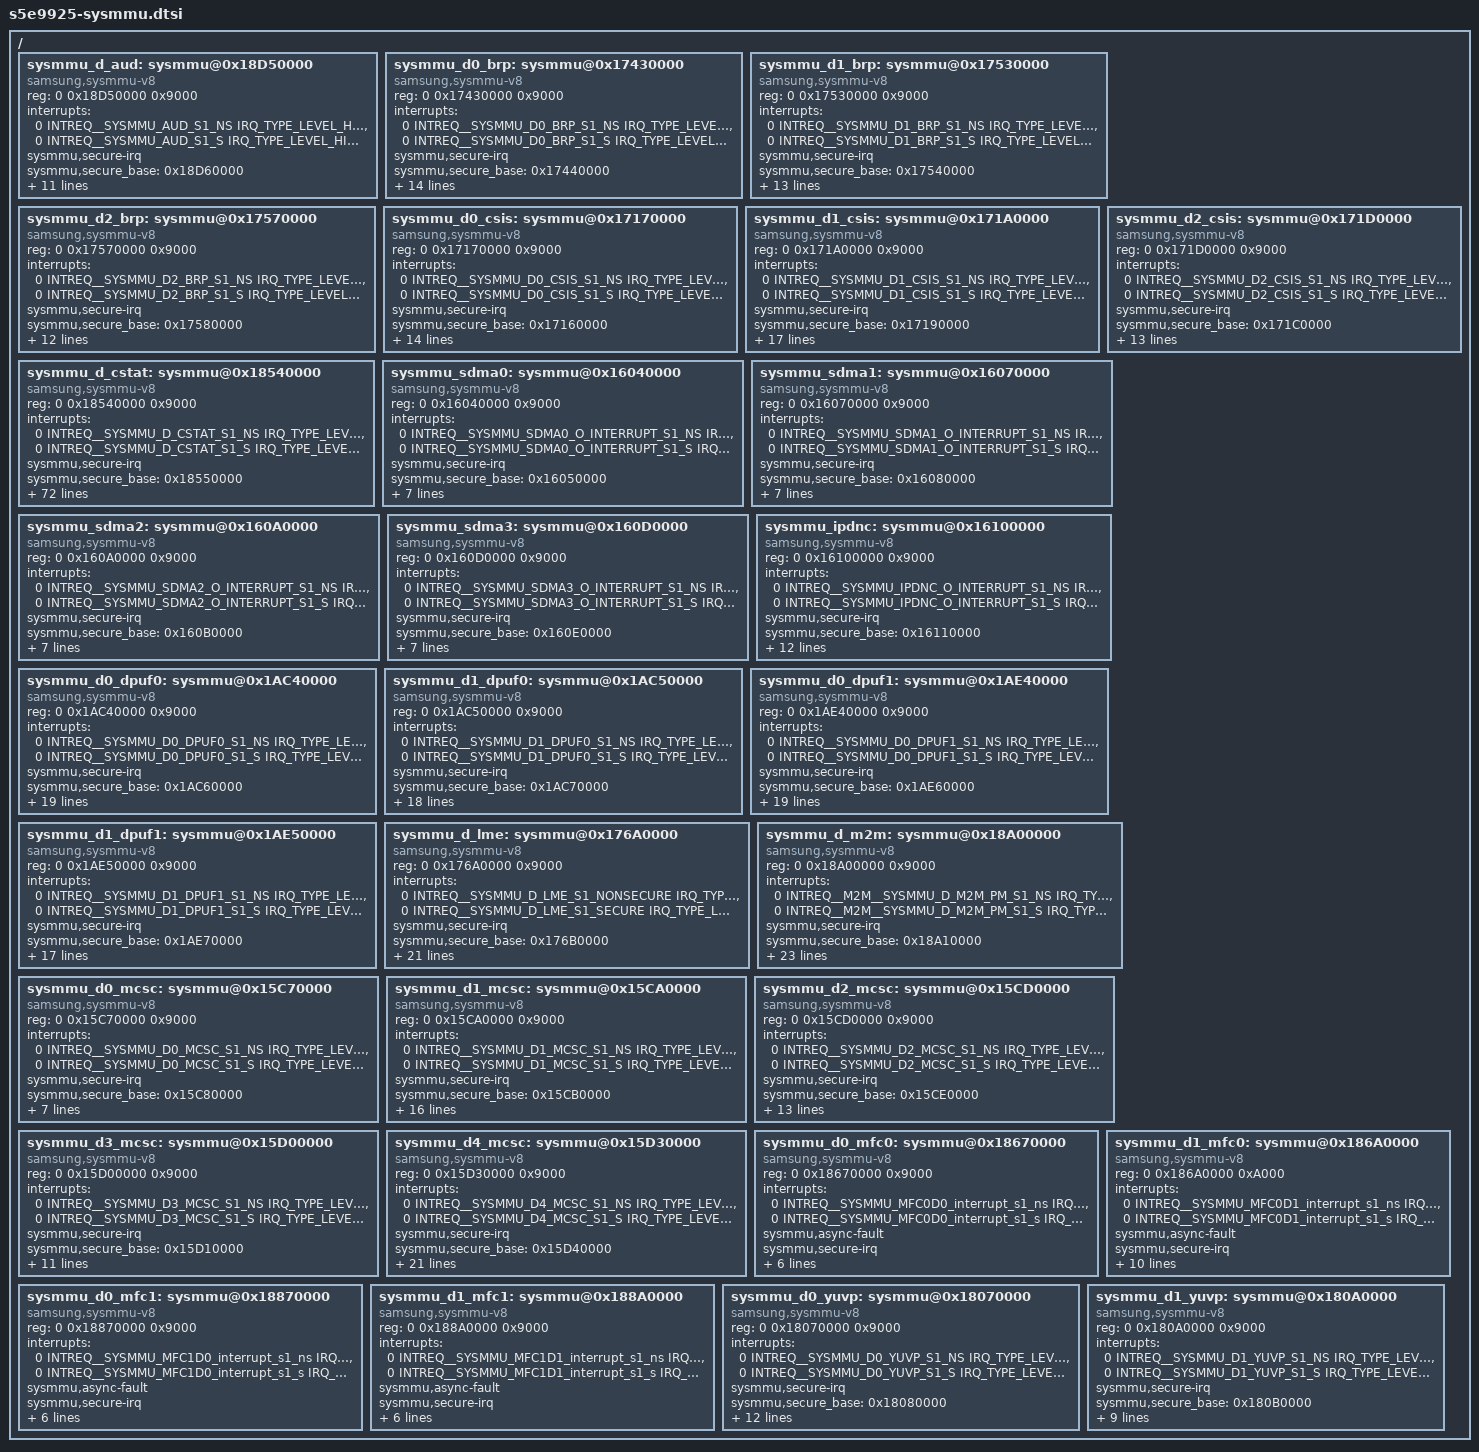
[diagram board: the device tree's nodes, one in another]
/*
 * SAMSUNG S5E9925 SoC device tree source
 *
 * Copyright (c) 2021 Samsung Electronics Co., Ltd.
 *		http://www.samsung.com
 *
 * SAMSUNG S5E9925 SoC device nodes are listed in this file.
 * S5E9925 based board files can include this file and provide
 * values for board specfic bindings.
 *
 * This program is free software; you can redistribute it and/or modify
 * it under the terms of the GNU General Public License version 2 as
 * published by the Free Software Foundation.
 */

#include <dt-bindings/interrupt-controller/arm-gic.h>
#include <dt-bindings/soc/samsung,sysmmu-v8.h>

/ {
	sysmmu_d_aud: sysmmu@0x18D50000 {
		compatible = "samsung,sysmmu-v8";
		reg = <0 0x18D50000 0x9000>;
		interrupts = <0 INTREQ__SYSMMU_AUD_S1_NS IRQ_TYPE_LEVEL_HIGH>,
				<0 INTREQ__SYSMMU_AUD_S1_S IRQ_TYPE_LEVEL_HIGH>;
		sysmmu,secure-irq;
		sysmmu,secure_base = <0x18D60000>;
		qos = <15>;
		#iommu-cells = <0>;
		sysmmu,default_tlb = <TLB_CFG(BL1, PREFETCH_NONE)>;
		sysmmu,tlb_property =
			<1 TLB_CFG(BL1, PREFETCH_NONE) DIR_RW SYSMMU_ID_MASK(0x3, 0xF)>,
			<2 TLB_CFG(BL1, PREFETCH_NONE) DIR_RW SYSMMU_ID_MASK(0x4, 0xF)>,
			<3 TLB_CFG(BL1, PREFETCH_NONE) DIR_RW SYSMMU_ID_MASK(0x5, 0xF)>,
			<4 TLB_CFG(BL1, PREFETCH_NONE) DIR_WRITE SYSMMU_ID_MASK(0x7, 0xF)>,
			<5 TLB_CFG(BL1, PREFETCH_NONE) DIR_WRITE SYSMMU_ID_MASK(0x8, 0xF)>;
		port-name = "ABOX (CA32_0), ABOX (UDMA), ...";
		power-domains = <&pd_aud>;
	};

	sysmmu_d0_brp: sysmmu@0x17430000 {
		compatible = "samsung,sysmmu-v8";
		reg = <0 0x17430000 0x9000>;
		interrupts = <0 INTREQ__SYSMMU_D0_BRP_S1_NS IRQ_TYPE_LEVEL_HIGH>,
				<0 INTREQ__SYSMMU_D0_BRP_S1_S IRQ_TYPE_LEVEL_HIGH>;
		sysmmu,secure-irq;
		sysmmu,secure_base = <0x17440000>;
		qos = <15>;
		#iommu-cells = <0>;
		sysmmu,default_tlb = <TLB_CFG(BL1, PREFETCH_PREDICTION)>;
		sysmmu,tlb_property =
			<1 TLB_CFG(BL1, PREFETCH_PREDICTION) DIR_READ SYSMMU_ID_MASK(0x0, 0xF)>,
			<2 TLB_CFG(BL1, PREFETCH_PREDICTION) DIR_READ SYSMMU_ID_MASK(0x8, 0xF)>,
			<8 TLB_CFG(BL1, PREFETCH_NONE) DIR_READ SYSMMU_ID_MASK(0x1, 0xF)>,
			<3 TLB_CFG(BL1, PREFETCH_PREDICTION) DIR_READ SYSMMU_ID_MASK(0x2, 0xF)>,
			<4 TLB_CFG(BL1, PREFETCH_PREDICTION) DIR_READ SYSMMU_ID_MASK(0xA, 0xF)>,
			<5 TLB_CFG(BL1, PREFETCH_NONE) DIR_WRITE SYSMMU_ID_MASK(0x3, 0xF)>,
			<6 TLB_CFG(BL1, PREFETCH_NONE) DIR_WRITE SYSMMU_ID_MASK(0x4, 0xF)>,
			<7 TLB_CFG(BL1, PREFETCH_NONE) DIR_WRITE SYSMMU_ID_MASK(0x5, 0xF)>;
		port-name = "BYRP(M0), BYRP(M1), BYRP(M2)...";
		power-domains = <&pd_brp>;
	};

	sysmmu_d1_brp: sysmmu@0x17530000 {
		compatible = "samsung,sysmmu-v8";
		reg = <0 0x17530000 0x9000>;
		interrupts = <0 INTREQ__SYSMMU_D1_BRP_S1_NS IRQ_TYPE_LEVEL_HIGH>,
				<0 INTREQ__SYSMMU_D1_BRP_S1_S IRQ_TYPE_LEVEL_HIGH>;
		sysmmu,secure-irq;
		sysmmu,secure_base = <0x17540000>;
		qos = <15>;
		#iommu-cells = <0>;
		sysmmu,default_tlb = <TLB_CFG(BL1, PREFETCH_PREDICTION)>;
		sysmmu,tlb_property =
			<7 TLB_CFG(BL1, PREFETCH_NONE) DIR_READ SYSMMU_ID_MASK(0x0, 0x7)>,
			<1 TLB_CFG(BL1, PREFETCH_PREDICTION) DIR_WRITE SYSMMU_ID_MASK(0x4, 0x7)>,
			<2 TLB_CFG(BL1, PREFETCH_PREDICTION) DIR_READ SYSMMU_ID_MASK(0x1, 0x7)>,
			<3 TLB_CFG(BL1, PREFETCH_PREDICTION) DIR_WRITE SYSMMU_ID_MASK(0x5, 0x7)>,
			<4 TLB_CFG(BL1, PREFETCH_PREDICTION) DIR_WRITE SYSMMU_ID_MASK(0x1, 0x7)>,
			<5 TLB_CFG(BL1, PREFETCH_PREDICTION) DIR_WRITE SYSMMU_ID_MASK(0x2, 0x7)>,
			<6 TLB_CFG(BL1, PREFETCH_NONE) DIR_WRITE SYSMMU_ID_MASK(0x3, 0x7)>;
		port-name = "RGBP (M0), RGBP (M0), RGBP (...";
		power-domains = <&pd_brp>;
	};

	sysmmu_d2_brp: sysmmu@0x17570000 {
		compatible = "samsung,sysmmu-v8";
		reg = <0 0x17570000 0x9000>;
		interrupts = <0 INTREQ__SYSMMU_D2_BRP_S1_NS IRQ_TYPE_LEVEL_HIGH>,
				<0 INTREQ__SYSMMU_D2_BRP_S1_S IRQ_TYPE_LEVEL_HIGH>;
		sysmmu,secure-irq;
		sysmmu,secure_base = <0x17580000>;
		qos = <15>;
		#iommu-cells = <0>;
		sysmmu,default_tlb = <TLB_CFG(BL1, PREFETCH_PREDICTION)>;
		sysmmu,tlb_property =
			<1 TLB_CFG(BL1, PREFETCH_PREDICTION) DIR_WRITE SYSMMU_ID_MASK(0x0, 0x7)>,
			<2 TLB_CFG(BL1, PREFETCH_PREDICTION) DIR_READ SYSMMU_ID_MASK(0x1, 0x7)>,
			<3 TLB_CFG(BL1, PREFETCH_PREDICTION) DIR_WRITE SYSMMU_ID_MASK(0x1, 0x7)>,
			<4 TLB_CFG(BL1, PREFETCH_PREDICTION) DIR_WRITE SYSMMU_ID_MASK(0x5, 0x7)>,
			<5 TLB_CFG(BL1, PREFETCH_PREDICTION) DIR_WRITE SYSMMU_ID_MASK(0x2, 0x7)>,
			<6 TLB_CFG(BL1, PREFETCH_NONE) DIR_WRITE SYSMMU_ID_MASK(0x3, 0x7)>;
		port-name = "RGBP (M1), RGBP (M1), RGBP (...";
		power-domains = <&pd_brp>;
	};

	sysmmu_d0_csis: sysmmu@0x17170000 {
		compatible = "samsung,sysmmu-v8";
		reg = <0 0x17170000 0x9000>;
		interrupts = <0 INTREQ__SYSMMU_D0_CSIS_S1_NS IRQ_TYPE_LEVEL_HIGH>,
				<0 INTREQ__SYSMMU_D0_CSIS_S1_S IRQ_TYPE_LEVEL_HIGH>;
		sysmmu,secure-irq;
		sysmmu,secure_base = <0x17160000>;
		qos = <15>;
		#iommu-cells = <0>;
		sysmmu,default_tlb = <TLB_CFG(BL1, PREFETCH_PREDICTION)>;
		sysmmu,tlb_property =
			<1 TLB_CFG(BL1, PREFETCH_PREDICTION) DIR_WRITE SYSMMU_ID_MASK(0x2, 0xF)>,
			<2 TLB_CFG(BL1, PREFETCH_PREDICTION) DIR_WRITE SYSMMU_ID_MASK(0x4, 0xF)>,
			<3 TLB_CFG(BL1, PREFETCH_PREDICTION) DIR_WRITE SYSMMU_ID_MASK(0x8, 0xF)>,
			<4 TLB_CFG(BL1, PREFETCH_PREDICTION) DIR_WRITE SYSMMU_ID_MASK(0xC, 0xF)>,
			<5 TLB_CFG(BL1, PREFETCH_PREDICTION) DIR_WRITE SYSMMU_ID_MASK(0x1, 0xF)>,
			<6 TLB_CFG(BL1, PREFETCH_PREDICTION) DIR_WRITE SYSMMU_ID_MASK(0x5, 0xF)>,
			<7 TLB_CFG(BL1, PREFETCH_PREDICTION) DIR_WRITE SYSMMU_ID_MASK(0x9, 0xF)>,
			<8 TLB_CFG(BL1, PREFETCH_PREDICTION) DIR_WRITE SYSMMU_ID_MASK(0xD, 0xF)>;
		port-name = "CSISX7_V1.0 (CSIS DMA0), CSI...";
		power-domains = <&pd_allcsis>;
	};

	sysmmu_d1_csis: sysmmu@0x171A0000 {
		compatible = "samsung,sysmmu-v8";
		reg = <0 0x171A0000 0x9000>;
		interrupts = <0 INTREQ__SYSMMU_D1_CSIS_S1_NS IRQ_TYPE_LEVEL_HIGH>,
				<0 INTREQ__SYSMMU_D1_CSIS_S1_S IRQ_TYPE_LEVEL_HIGH>;
		sysmmu,secure-irq;
		sysmmu,secure_base = <0x17190000>;
		qos = <15>;
		#iommu-cells = <0>;
		sysmmu,default_tlb = <TLB_CFG(BL1, PREFETCH_PREDICTION)>;
		sysmmu,tlb_property =
			<1 TLB_CFG(BL1, PREFETCH_PREDICTION) DIR_WRITE SYSMMU_ID_MASK(0x8, 0x1F)>,
			<2 TLB_CFG(BL1, PREFETCH_PREDICTION) DIR_WRITE SYSMMU_ID_MASK(0x10, 0x1F)>,
			<3 TLB_CFG(BL1, PREFETCH_PREDICTION) DIR_WRITE SYSMMU_ID_MASK(0x18, 0x1F)>,
			<4 TLB_CFG(BL1, PREFETCH_PREDICTION) DIR_WRITE SYSMMU_ID_MASK(0x1, 0x1F)>,
			<5 TLB_CFG(BL1, PREFETCH_PREDICTION) DIR_WRITE SYSMMU_ID_MASK(0x9, 0x1F)>,
			<6 TLB_CFG(BL1, PREFETCH_PREDICTION) DIR_WRITE SYSMMU_ID_MASK(0x11, 0x1F)>,
			<7 TLB_CFG(BL1, PREFETCH_PREDICTION) DIR_WRITE SYSMMU_ID_MASK(0x19, 0x1F)>,
			<8 TLB_CFG(BL1, PREFETCH_PREDICTION) DIR_WRITE SYSMMU_ID_MASK(0x2, 0x1F)>,
			<9 TLB_CFG(BL1, PREFETCH_PREDICTION) DIR_WRITE SYSMMU_ID_MASK(0xA, 0x1F)>,
			<10 TLB_CFG(BL1, PREFETCH_PREDICTION) DIR_WRITE SYSMMU_ID_MASK(0x12, 0x1F)>,
			<11 TLB_CFG(BL1, PREFETCH_PREDICTION) DIR_WRITE SYSMMU_ID_MASK(0x1A, 0x1F)>;
		port-name = "CSISX7_V1.0 (CSIS DMA2), CSI...";
		power-domains = <&pd_allcsis>;
	};

	sysmmu_d2_csis: sysmmu@0x171D0000 {
		compatible = "samsung,sysmmu-v8";
		reg = <0 0x171D0000 0x9000>;
		interrupts = <0 INTREQ__SYSMMU_D2_CSIS_S1_NS IRQ_TYPE_LEVEL_HIGH>,
				<0 INTREQ__SYSMMU_D2_CSIS_S1_S IRQ_TYPE_LEVEL_HIGH>;
		sysmmu,secure-irq;
		sysmmu,secure_base = <0x171C0000>;
		qos = <15>;
		#iommu-cells = <0>;
		sysmmu,default_tlb = <TLB_CFG(BL1, PREFETCH_PREDICTION)>;
		sysmmu,tlb_property =
			<1 TLB_CFG(BL1, PREFETCH_PREDICTION) DIR_READ SYSMMU_ID_MASK(0x0, 0x7F)>,
			<2 TLB_CFG(BL1, PREFETCH_PREDICTION) DIR_WRITE SYSMMU_ID_MASK(0x20, 0x7F)>,
			<3 TLB_CFG(BL1, PREFETCH_PREDICTION) DIR_WRITE SYSMMU_ID_MASK(0x40, 0x7F)>,
			<4 TLB_CFG(BL1, PREFETCH_PREDICTION) DIR_WRITE SYSMMU_ID_MASK(0x60, 0x7F)>,
			<5 TLB_CFG(BL1, PREFETCH_NONE) DIR_WRITE SYSMMU_ID_MASK(0x1, 0x7)>,
			<6 TLB_CFG(BL1, PREFETCH_NONE) DIR_WRITE SYSMMU_ID_MASK(0x2, 0x7)>,
			<7 TLB_CFG(BL1, PREFETCH_NONE) DIR_WRITE SYSMMU_ID_MASK(0x3, 0x7)>;
		port-name = "PDP_TOP_(PDP_STAT_IMG0_AF0),...";
		power-domains = <&pd_allcsis>;
	};

	sysmmu_d_cstat: sysmmu@0x18540000 {
		compatible = "samsung,sysmmu-v8";
		reg = <0 0x18540000 0x9000>;
		interrupts = <0 INTREQ__SYSMMU_D_CSTAT_S1_NS IRQ_TYPE_LEVEL_HIGH>,
				<0 INTREQ__SYSMMU_D_CSTAT_S1_S IRQ_TYPE_LEVEL_HIGH>;
		sysmmu,secure-irq;
		sysmmu,secure_base = <0x18550000>;
		qos = <15>;
		#iommu-cells = <0>;
		sysmmu,default_tlb = <TLB_CFG(BL1, PREFETCH_PREDICTION)>;
		sysmmu,tlb_property =
			<1 TLB_CFG(BL1, PREFETCH_PREDICTION) DIR_WRITE SYSMMU_ID_MASK(0x80, 0x3FF)>,
			<2 TLB_CFG(BL1, PREFETCH_PREDICTION) DIR_WRITE SYSMMU_ID_MASK(0x100, 0x3FF)>,
			<3 TLB_CFG(BL1, PREFETCH_PREDICTION) DIR_WRITE SYSMMU_ID_MASK(0x180, 0x3FF)>,
			<4 TLB_CFG(BL1, PREFETCH_PREDICTION) DIR_READ SYSMMU_ID_MASK(0x0, 0x3FF)>,
			<5 TLB_CFG(BL1, PREFETCH_PREDICTION) DIR_WRITE SYSMMU_ID_MASK(0x1, 0x3FF)>,
			<6 TLB_CFG(BL1, PREFETCH_PREDICTION) DIR_WRITE SYSMMU_ID_MASK(0x81, 0x3FF)>,
			<7 TLB_CFG(BL1, PREFETCH_PREDICTION) DIR_WRITE SYSMMU_ID_MASK(0x101, 0x3FF)>,
			<8 TLB_CFG(BL1, PREFETCH_PREDICTION) DIR_WRITE SYSMMU_ID_MASK(0x181, 0x3FF)>,
			<9 TLB_CFG(BL1, PREFETCH_PREDICTION) DIR_READ SYSMMU_ID_MASK(0x1, 0x3FF)>,
			<10 TLB_CFG(BL1, PREFETCH_PREDICTION) DIR_WRITE SYSMMU_ID_MASK(0x2, 0x3FF)>,
			<11 TLB_CFG(BL1, PREFETCH_PREDICTION) DIR_WRITE SYSMMU_ID_MASK(0x82, 0x3FF)>,
			<12 TLB_CFG(BL1, PREFETCH_PREDICTION) DIR_WRITE SYSMMU_ID_MASK(0x102, 0x3FF)>,
			<13 TLB_CFG(BL1, PREFETCH_PREDICTION) DIR_WRITE SYSMMU_ID_MASK(0x182, 0x3FF)>,
			<14 TLB_CFG(BL1, PREFETCH_PREDICTION) DIR_READ SYSMMU_ID_MASK(0x2, 0x3FF)>,
			<15 TLB_CFG(BL1, PREFETCH_PREDICTION) DIR_WRITE SYSMMU_ID_MASK(0x3, 0x3FF)>,
			<16 TLB_CFG(BL1, PREFETCH_PREDICTION) DIR_WRITE SYSMMU_ID_MASK(0x83, 0x3FF)>,
			<17 TLB_CFG(BL1, PREFETCH_PREDICTION) DIR_WRITE SYSMMU_ID_MASK(0x103, 0x3FF)>,
			<18 TLB_CFG(BL1, PREFETCH_PREDICTION) DIR_WRITE SYSMMU_ID_MASK(0x183, 0x3FF)>,
			<19 TLB_CFG(BL1, PREFETCH_PREDICTION) DIR_READ SYSMMU_ID_MASK(0x3, 0x3FF)>,
			<20 TLB_CFG(BL1, PREFETCH_PREDICTION) DIR_WRITE SYSMMU_ID_MASK(0x4, 0x3FF)>,
			<21 TLB_CFG(BL1, PREFETCH_PREDICTION) DIR_WRITE SYSMMU_ID_MASK(0x84, 0x3FF)>,
			<22 TLB_CFG(BL1, PREFETCH_PREDICTION) DIR_WRITE SYSMMU_ID_MASK(0x104, 0x3FF)>,
			<23 TLB_CFG(BL1, PREFETCH_PREDICTION) DIR_WRITE SYSMMU_ID_MASK(0x184, 0x3FF)>,
			<60 TLB_CFG(BL1, PREFETCH_NONE) DIR_READ SYSMMU_ID_MASK(0x4, 0x3FF)>,
			<24 TLB_CFG(BL1, PREFETCH_PREDICTION) DIR_WRITE SYSMMU_ID_MASK(0x5, 0x3FF)>,
			<25 TLB_CFG(BL1, PREFETCH_PREDICTION) DIR_WRITE SYSMMU_ID_MASK(0x85, 0x3FF)>,
			<26 TLB_CFG(BL1, PREFETCH_PREDICTION) DIR_WRITE SYSMMU_ID_MASK(0x105, 0x3FF)>,
			<27 TLB_CFG(BL1, PREFETCH_PREDICTION) DIR_WRITE SYSMMU_ID_MASK(0x185, 0x3FF)>,
			<61 TLB_CFG(BL1, PREFETCH_NONE) DIR_READ SYSMMU_ID_MASK(0x5, 0x3FF)>,
			<28 TLB_CFG(BL1, PREFETCH_PREDICTION) DIR_WRITE SYSMMU_ID_MASK(0x6, 0x3FF)>,
			<29 TLB_CFG(BL1, PREFETCH_PREDICTION) DIR_WRITE SYSMMU_ID_MASK(0x86, 0x3FF)>,
			<30 TLB_CFG(BL1, PREFETCH_PREDICTION) DIR_WRITE SYSMMU_ID_MASK(0x106, 0x3FF)>,
			<31 TLB_CFG(BL1, PREFETCH_PREDICTION) DIR_WRITE SYSMMU_ID_MASK(0x186, 0x3FF)>,
			<62 TLB_CFG(BL1, PREFETCH_NONE) DIR_READ SYSMMU_ID_MASK(0x6, 0x3FF)>,
			<32 TLB_CFG(BL1, PREFETCH_PREDICTION) DIR_WRITE SYSMMU_ID_MASK(0x7, 0x3FF)>,
			<33 TLB_CFG(BL1, PREFETCH_PREDICTION) DIR_WRITE SYSMMU_ID_MASK(0x87, 0x3FF)>,
			<34 TLB_CFG(BL1, PREFETCH_PREDICTION) DIR_WRITE SYSMMU_ID_MASK(0x107, 0x3FF)>,
			<35 TLB_CFG(BL1, PREFETCH_PREDICTION) DIR_WRITE SYSMMU_ID_MASK(0x187, 0x3FF)>,
			<63 TLB_CFG(BL1, PREFETCH_NONE) DIR_READ SYSMMU_ID_MASK(0x7, 0x3FF)>,
			<36 TLB_CFG(BL1, PREFETCH_PREDICTION) DIR_WRITE SYSMMU_ID_MASK(0x8, 0x3FF)>,
			<37 TLB_CFG(BL1, PREFETCH_PREDICTION) DIR_WRITE SYSMMU_ID_MASK(0x28, 0x3FF)>,
			<38 TLB_CFG(BL1, PREFETCH_PREDICTION) DIR_WRITE SYSMMU_ID_MASK(0x48, 0x3FF)>,
			<39 TLB_CFG(BL1, PREFETCH_PREDICTION) DIR_WRITE SYSMMU_ID_MASK(0x88, 0x3FF)>,
			<40 TLB_CFG(BL1, PREFETCH_PREDICTION) DIR_WRITE SYSMMU_ID_MASK(0xA8, 0x3FF)>,
			<41 TLB_CFG(BL1, PREFETCH_PREDICTION) DIR_WRITE SYSMMU_ID_MASK(0xC8, 0x3FF)>,
			<42 TLB_CFG(BL1, PREFETCH_PREDICTION) DIR_WRITE SYSMMU_ID_MASK(0x108, 0x3FF)>,
			<43 TLB_CFG(BL1, PREFETCH_PREDICTION) DIR_WRITE SYSMMU_ID_MASK(0x128, 0x3FF)>,
			<44 TLB_CFG(BL1, PREFETCH_PREDICTION) DIR_WRITE SYSMMU_ID_MASK(0x148, 0x3FF)>,
			<45 TLB_CFG(BL1, PREFETCH_PREDICTION) DIR_WRITE SYSMMU_ID_MASK(0x188, 0x3FF)>,
			<46 TLB_CFG(BL1, PREFETCH_PREDICTION) DIR_WRITE SYSMMU_ID_MASK(0x1A8, 0x3FF)>,
			<47 TLB_CFG(BL1, PREFETCH_PREDICTION) DIR_WRITE SYSMMU_ID_MASK(0x1C8, 0x3FF)>,
			<48 TLB_CFG(BL1, PREFETCH_PREDICTION) DIR_WRITE SYSMMU_ID_MASK(0x9, 0x3FF)>,
			<49 TLB_CFG(BL1, PREFETCH_PREDICTION) DIR_WRITE SYSMMU_ID_MASK(0x29, 0x3FF)>,
			<50 TLB_CFG(BL1, PREFETCH_PREDICTION) DIR_WRITE SYSMMU_ID_MASK(0x49, 0x3FF)>,
			<51 TLB_CFG(BL1, PREFETCH_PREDICTION) DIR_WRITE SYSMMU_ID_MASK(0x89, 0x3FF)>,
			<52 TLB_CFG(BL1, PREFETCH_PREDICTION) DIR_WRITE SYSMMU_ID_MASK(0xA9, 0x3FF)>,
			<53 TLB_CFG(BL1, PREFETCH_PREDICTION) DIR_WRITE SYSMMU_ID_MASK(0xC9, 0x3FF)>,
			<54 TLB_CFG(BL1, PREFETCH_PREDICTION) DIR_WRITE SYSMMU_ID_MASK(0x109, 0x3FF)>,
			<55 TLB_CFG(BL1, PREFETCH_PREDICTION) DIR_WRITE SYSMMU_ID_MASK(0x129, 0x3FF)>,
			<56 TLB_CFG(BL1, PREFETCH_PREDICTION) DIR_WRITE SYSMMU_ID_MASK(0x149, 0x3FF)>,
			<57 TLB_CFG(BL1, PREFETCH_PREDICTION) DIR_WRITE SYSMMU_ID_MASK(0x189, 0x3FF)>,
			<58 TLB_CFG(BL1, PREFETCH_PREDICTION) DIR_WRITE SYSMMU_ID_MASK(0x1A9, 0x3FF)>,
			<59 TLB_CFG(BL1, PREFETCH_PREDICTION) DIR_WRITE SYSMMU_ID_MASK(0x1C9, 0x3FF)>,
			<64 TLB_CFG(BL1, PREFETCH_NONE) DIR_WRITE SYSMMU_ID_MASK(0xA, 0x3F)>,
			<65 TLB_CFG(BL1, PREFETCH_NONE) DIR_WRITE SYSMMU_ID_MASK(0xB, 0x3F)>,
			<66 TLB_CFG(BL1, PREFETCH_NONE) DIR_WRITE SYSMMU_ID_MASK(0xC, 0x3F)>;
		port-name = "CSTAT_RD0_RGBYHIST, CSTAT_RD...";
		power-domains = <&pd_cstat>;
	};

	sysmmu_sdma0: sysmmu@0x16040000 {
		compatible = "samsung,sysmmu-v8";
		reg = <0 0x16040000 0x9000>;
		interrupts = <0 INTREQ__SYSMMU_SDMA0_O_INTERRUPT_S1_NS IRQ_TYPE_LEVEL_HIGH>,
				<0 INTREQ__SYSMMU_SDMA0_O_INTERRUPT_S1_S IRQ_TYPE_LEVEL_HIGH>;
		sysmmu,secure-irq;
		sysmmu,secure_base = <0x16050000>;
		qos = <15>;
		#iommu-cells = <0>;
		sysmmu,default_tlb = <TLB_CFG(BL1, PREFETCH_NONE)>;
		sysmmu,tlb_property =
			<1 TLB_CFG(BL8, PREFETCH_NONE) DIR_RW SYSMMU_ID_MASK(0x0, 0x40)>;
		port-name = "IP_SDMA (BUSD0)";
		power-domains = <&pd_dnc>;
	};

	sysmmu_sdma1: sysmmu@0x16070000 {
		compatible = "samsung,sysmmu-v8";
		reg = <0 0x16070000 0x9000>;
		interrupts = <0 INTREQ__SYSMMU_SDMA1_O_INTERRUPT_S1_NS IRQ_TYPE_LEVEL_HIGH>,
				<0 INTREQ__SYSMMU_SDMA1_O_INTERRUPT_S1_S IRQ_TYPE_LEVEL_HIGH>;
		sysmmu,secure-irq;
		sysmmu,secure_base = <0x16080000>;
		qos = <15>;
		#iommu-cells = <0>;
		sysmmu,default_tlb = <TLB_CFG(BL1, PREFETCH_NONE)>;
		sysmmu,tlb_property =
			<1 TLB_CFG(BL8, PREFETCH_NONE) DIR_RW SYSMMU_ID_MASK(0x0, 0x40)>;
		port-name = "IP_SDMA (BUSD0)";
		power-domains = <&pd_dnc>;
	};

	sysmmu_sdma2: sysmmu@0x160A0000 {
		compatible = "samsung,sysmmu-v8";
		reg = <0 0x160A0000 0x9000>;
		interrupts = <0 INTREQ__SYSMMU_SDMA2_O_INTERRUPT_S1_NS IRQ_TYPE_LEVEL_HIGH>,
				<0 INTREQ__SYSMMU_SDMA2_O_INTERRUPT_S1_S IRQ_TYPE_LEVEL_HIGH>;
		sysmmu,secure-irq;
		sysmmu,secure_base = <0x160B0000>;
		qos = <15>;
		#iommu-cells = <0>;
		sysmmu,default_tlb = <TLB_CFG(BL1, PREFETCH_NONE)>;
		sysmmu,tlb_property =
			<1 TLB_CFG(BL8, PREFETCH_NONE) DIR_RW SYSMMU_ID_MASK(0x0, 0x40)>;
		port-name = "IP_SDMA (BUSD0)";
		power-domains = <&pd_dnc>;
	};

	sysmmu_sdma3: sysmmu@0x160D0000 {
		compatible = "samsung,sysmmu-v8";
		reg = <0 0x160D0000 0x9000>;
		interrupts = <0 INTREQ__SYSMMU_SDMA3_O_INTERRUPT_S1_NS IRQ_TYPE_LEVEL_HIGH>,
				<0 INTREQ__SYSMMU_SDMA3_O_INTERRUPT_S1_S IRQ_TYPE_LEVEL_HIGH>;
		sysmmu,secure-irq;
		sysmmu,secure_base = <0x160E0000>;
		qos = <15>;
		#iommu-cells = <0>;
		sysmmu,default_tlb = <TLB_CFG(BL1, PREFETCH_NONE)>;
		sysmmu,tlb_property =
			<1 TLB_CFG(BL8, PREFETCH_NONE) DIR_RW SYSMMU_ID_MASK(0x0, 0x40)>;
		port-name = "IP_SDMA (BUSD0)";
		power-domains = <&pd_dnc>;
	};

	sysmmu_ipdnc: sysmmu@0x16100000 {
		compatible = "samsung,sysmmu-v8";
		reg = <0 0x16100000 0x9000>;
		interrupts = <0 INTREQ__SYSMMU_IPDNC_O_INTERRUPT_S1_NS IRQ_TYPE_LEVEL_HIGH>,
				<0 INTREQ__SYSMMU_IPDNC_O_INTERRUPT_S1_S IRQ_TYPE_LEVEL_HIGH>;
		sysmmu,secure-irq;
		sysmmu,secure_base = <0x16110000>;
		qos = <15>;
		#iommu-cells = <0>;
		sysmmu,default_tlb = <TLB_CFG(BL1, PREFETCH_NONE)>;
		sysmmu,tlb_property =
			<1 TLB_CFG(BL1, PREFETCH_NONE) DIR_READ SYSMMU_ID_MASK(0x2, 0xF)>,
			<2 TLB_CFG(BL1, PREFETCH_PREDICTION) DIR_READ SYSMMU_ID_MASK(0xA, 0xF)>,
			<3 TLB_CFG(BL1, PREFETCH_PREDICTION) DIR_READ SYSMMU_ID_MASK(0x9, 0xF)>,
			<4 TLB_CFG(BL1, PREFETCH_PREDICTION) DIR_READ SYSMMU_ID_MASK(0x3, 0x7)>,
			<5 TLB_CFG(BL1, PREFETCH_NONE) DIR_RW SYSMMU_ID_MASK(0x0, 0x7)>,
			<6 TLB_CFG(BL1, PREFETCH_NONE) DIR_WRITE SYSMMU_ID_MASK(0x4, 0x7)>;
		port-name = "IP_DNC (DRAM)";
		power-domains = <&pd_dnc>;
	};

	sysmmu_d0_dpuf0: sysmmu@0x1AC40000 {
		compatible = "samsung,sysmmu-v8";
		reg = <0 0x1AC40000 0x9000>;
		interrupts = <0 INTREQ__SYSMMU_D0_DPUF0_S1_NS IRQ_TYPE_LEVEL_HIGH>,
				<0 INTREQ__SYSMMU_D0_DPUF0_S1_S IRQ_TYPE_LEVEL_HIGH>;
		sysmmu,secure-irq;
		sysmmu,secure_base = <0x1AC60000>;
		qos = <15>;
		#iommu-cells = <0>;
		sysmmu,default_tlb = <TLB_CFG(BL32, PREFETCH_PREDICTION)>;
		sysmmu,tlb_property =
			<2 TLB_CFG(BL16, PREFETCH_PREDICTION) DIR_READ SYSMMU_ID_MASK(0x0, 0x1F)>,
			<4 TLB_CFG(BL2, PREFETCH_PREDICTION) DIR_READ SYSMMU_ID_MASK(0x2, 0x1F)>,
			<1 TLB_CFG(BL32, PREFETCH_PREDICTION) DIR_READ SYSMMU_ID_MASK(0x5, 0x1F)>,
			<5 TLB_CFG(BL2, PREFETCH_PREDICTION) DIR_READ SYSMMU_ID_MASK(0x6, 0x1F)>,
			<9 TLB_CFG(BL1, PREFETCH_PREDICTION) DIR_READ SYSMMU_ID_MASK(0x7, 0x1F)>,
			<3 TLB_CFG(BL16, PREFETCH_PREDICTION) DIR_READ SYSMMU_ID_MASK(0x8, 0x1F)>,
			<6 TLB_CFG(BL2, PREFETCH_PREDICTION) DIR_READ SYSMMU_ID_MASK(0xA, 0x1F)>,
			<7 TLB_CFG(BL2, PREFETCH_PREDICTION) DIR_READ SYSMMU_ID_MASK(0xC, 0x1F)>,
			<8 TLB_CFG(BL2, PREFETCH_PREDICTION) DIR_READ SYSMMU_ID_MASK(0xD, 0x1F)>,
			<10 TLB_CFG(BL1, PREFETCH_PREDICTION) DIR_READ SYSMMU_ID_MASK(0x10, 0x1F)>,
			<11 TLB_CFG(BL1, PREFETCH_PREDICTION) DIR_READ SYSMMU_ID_MASK(0x14, 0x1F)>,
			<12 TLB_CFG(BL1, PREFETCH_PREDICTION) DIR_WRITE SYSMMU_ID_MASK(0x0, 0x1F)>,
			<13 TLB_CFG(BL1, PREFETCH_PREDICTION) DIR_WRITE SYSMMU_ID_MASK(0x1, 0x1F)>;
		port-name = "DPU_DMA_TOP";
		power-domains = <&pd_dpuf>;
	};

	sysmmu_d1_dpuf0: sysmmu@0x1AC50000 {
		compatible = "samsung,sysmmu-v8";
		reg = <0 0x1AC50000 0x9000>;
		interrupts = <0 INTREQ__SYSMMU_D1_DPUF0_S1_NS IRQ_TYPE_LEVEL_HIGH>,
				<0 INTREQ__SYSMMU_D1_DPUF0_S1_S IRQ_TYPE_LEVEL_HIGH>;
		sysmmu,secure-irq;
		sysmmu,secure_base = <0x1AC70000>;
		qos = <15>;
		#iommu-cells = <0>;
		sysmmu,default_tlb = <TLB_CFG(BL16, PREFETCH_PREDICTION)>;
		sysmmu,tlb_property =
			<2 TLB_CFG(BL2, PREFETCH_PREDICTION) DIR_READ SYSMMU_ID_MASK(0x2, 0x1F)>,
			<3 TLB_CFG(BL2, PREFETCH_PREDICTION) DIR_READ SYSMMU_ID_MASK(0x4, 0x1F)>,
			<4 TLB_CFG(BL2, PREFETCH_PREDICTION) DIR_READ SYSMMU_ID_MASK(0x5, 0x1F)>,
			<8 TLB_CFG(BL1, PREFETCH_PREDICTION) DIR_READ SYSMMU_ID_MASK(0x6, 0x1F)>,
			<9 TLB_CFG(BL1, PREFETCH_PREDICTION) DIR_READ SYSMMU_ID_MASK(0x7, 0x1F)>,
			<1 TLB_CFG(BL16, PREFETCH_PREDICTION) DIR_READ SYSMMU_ID_MASK(0x8, 0x1F)>,
			<5 TLB_CFG(BL2, PREFETCH_PREDICTION) DIR_READ SYSMMU_ID_MASK(0xA, 0x1F)>,
			<6 TLB_CFG(BL2, PREFETCH_PREDICTION) DIR_READ SYSMMU_ID_MASK(0xC, 0x1F)>,
			<7 TLB_CFG(BL2, PREFETCH_PREDICTION) DIR_READ SYSMMU_ID_MASK(0xD, 0x1F)>,
			<10 TLB_CFG(BL1, PREFETCH_PREDICTION) DIR_READ SYSMMU_ID_MASK(0x10, 0x1F)>,
			<11 TLB_CFG(BL1, PREFETCH_NONE) DIR_WRITE SYSMMU_ID_MASK(0x10, 0x1F)>,
			<12 TLB_CFG(BL1, PREFETCH_NONE) DIR_WRITE SYSMMU_ID_MASK(0x14, 0x1F)>;
		port-name = "DPU_DMA_TOP";
		power-domains = <&pd_dpuf>;
	};

	sysmmu_d0_dpuf1: sysmmu@0x1AE40000 {
		compatible = "samsung,sysmmu-v8";
		reg = <0 0x1AE40000 0x9000>;
		interrupts = <0 INTREQ__SYSMMU_D0_DPUF1_S1_NS IRQ_TYPE_LEVEL_HIGH>,
				<0 INTREQ__SYSMMU_D0_DPUF1_S1_S IRQ_TYPE_LEVEL_HIGH>;
		sysmmu,secure-irq;
		sysmmu,secure_base = <0x1AE60000>;
		qos = <15>;
		#iommu-cells = <0>;
		sysmmu,default_tlb = <TLB_CFG(BL32, PREFETCH_PREDICTION)>;
		sysmmu,tlb_property =
			<2 TLB_CFG(BL16, PREFETCH_PREDICTION) DIR_READ SYSMMU_ID_MASK(0x0, 0x1F)>,
			<4 TLB_CFG(BL2, PREFETCH_PREDICTION) DIR_READ SYSMMU_ID_MASK(0x2, 0x1F)>,
			<1 TLB_CFG(BL32, PREFETCH_PREDICTION) DIR_READ SYSMMU_ID_MASK(0x5, 0x1F)>,
			<5 TLB_CFG(BL2, PREFETCH_PREDICTION) DIR_READ SYSMMU_ID_MASK(0x6, 0x1F)>,
			<9 TLB_CFG(BL1, PREFETCH_PREDICTION) DIR_READ SYSMMU_ID_MASK(0x7, 0x1F)>,
			<3 TLB_CFG(BL16, PREFETCH_PREDICTION) DIR_READ SYSMMU_ID_MASK(0x8, 0x1F)>,
			<6 TLB_CFG(BL2, PREFETCH_PREDICTION) DIR_READ SYSMMU_ID_MASK(0xA, 0x1F)>,
			<7 TLB_CFG(BL2, PREFETCH_PREDICTION) DIR_READ SYSMMU_ID_MASK(0xC, 0x1F)>,
			<8 TLB_CFG(BL2, PREFETCH_PREDICTION) DIR_READ SYSMMU_ID_MASK(0xD, 0x1F)>,
			<10 TLB_CFG(BL1, PREFETCH_PREDICTION) DIR_READ SYSMMU_ID_MASK(0x10, 0x1F)>,
			<11 TLB_CFG(BL1, PREFETCH_PREDICTION) DIR_READ SYSMMU_ID_MASK(0x14, 0x1F)>,
			<12 TLB_CFG(BL1, PREFETCH_PREDICTION) DIR_WRITE SYSMMU_ID_MASK(0x0, 0x1F)>,
			<13 TLB_CFG(BL1, PREFETCH_PREDICTION) DIR_WRITE SYSMMU_ID_MASK(0x1, 0x1F)>;
		port-name = "DPU_DMA_TOP";
		power-domains = <&pd_dpuf>;
	};

	sysmmu_d1_dpuf1: sysmmu@0x1AE50000 {
		compatible = "samsung,sysmmu-v8";
		reg = <0 0x1AE50000 0x9000>;
		interrupts = <0 INTREQ__SYSMMU_D1_DPUF1_S1_NS IRQ_TYPE_LEVEL_HIGH>,
				<0 INTREQ__SYSMMU_D1_DPUF1_S1_S IRQ_TYPE_LEVEL_HIGH>;
		sysmmu,secure-irq;
		sysmmu,secure_base = <0x1AE70000>;
		qos = <15>;
		#iommu-cells = <0>;
		sysmmu,default_tlb = <TLB_CFG(BL16, PREFETCH_PREDICTION)>;
		sysmmu,tlb_property =
			<2 TLB_CFG(BL2, PREFETCH_PREDICTION) DIR_READ SYSMMU_ID_MASK(0x2, 0x1F)>,
			<3 TLB_CFG(BL2, PREFETCH_PREDICTION) DIR_READ SYSMMU_ID_MASK(0x4, 0x1F)>,
			<4 TLB_CFG(BL2, PREFETCH_PREDICTION) DIR_READ SYSMMU_ID_MASK(0x5, 0x1F)>,
			<8 TLB_CFG(BL1, PREFETCH_PREDICTION) DIR_READ SYSMMU_ID_MASK(0x6, 0x1F)>,
			<9 TLB_CFG(BL1, PREFETCH_PREDICTION) DIR_READ SYSMMU_ID_MASK(0x7, 0x1F)>,
			<1 TLB_CFG(BL16, PREFETCH_PREDICTION) DIR_READ SYSMMU_ID_MASK(0x8, 0x1F)>,
			<5 TLB_CFG(BL2, PREFETCH_PREDICTION) DIR_READ SYSMMU_ID_MASK(0xA, 0x1F)>,
			<6 TLB_CFG(BL2, PREFETCH_PREDICTION) DIR_READ SYSMMU_ID_MASK(0xC, 0x1F)>,
			<7 TLB_CFG(BL2, PREFETCH_PREDICTION) DIR_READ SYSMMU_ID_MASK(0xD, 0x1F)>,
			<10 TLB_CFG(BL1, PREFETCH_NONE) DIR_WRITE SYSMMU_ID_MASK(0x10, 0x1F)>,
			<11 TLB_CFG(BL1, PREFETCH_NONE) DIR_WRITE SYSMMU_ID_MASK(0x14, 0x1F)>;
		port-name = "DPU_DMA_TOP";
		power-domains = <&pd_dpuf>;
	};

	sysmmu_d_lme: sysmmu@0x176A0000 {
		compatible = "samsung,sysmmu-v8";
		reg = <0 0x176A0000 0x9000>;
		interrupts = <0 INTREQ__SYSMMU_D_LME_S1_NONSECURE IRQ_TYPE_LEVEL_HIGH>,
				<0 INTREQ__SYSMMU_D_LME_S1_SECURE IRQ_TYPE_LEVEL_HIGH>;
		sysmmu,secure-irq;
		sysmmu,secure_base = <0x176B0000>;
		qos = <15>;
		#iommu-cells = <0>;
		sysmmu,default_tlb = <TLB_CFG(BL32, PREFETCH_PREDICTION)>;
		sysmmu,tlb_property =
			<5 TLB_CFG(BL1, PREFETCH_PREDICTION) DIR_READ SYSMMU_ID_MASK(0x8, 0x1F)>,
			<2 TLB_CFG(BL8, PREFETCH_PREDICTION) DIR_WRITE SYSMMU_ID_MASK(0x0, 0x1F)>,
			<6 TLB_CFG(BL1, PREFETCH_PREDICTION) DIR_WRITE SYSMMU_ID_MASK(0x8, 0x1F)>,
			<3 TLB_CFG(BL8, PREFETCH_PREDICTION) DIR_WRITE SYSMMU_ID_MASK(0x10, 0x1F)>,
			<7 TLB_CFG(BL1, PREFETCH_PREDICTION) DIR_WRITE SYSMMU_ID_MASK(0x18, 0x1F)>,
			<1 TLB_CFG(BL32, PREFETCH_PREDICTION) DIR_READ SYSMMU_ID_MASK(0x1, 0xF)>,
			<8 TLB_CFG(BL1, PREFETCH_PREDICTION) DIR_READ SYSMMU_ID_MASK(0x9, 0xF)>,
			<15 TLB_CFG(BL1, PREFETCH_NONE) DIR_WRITE SYSMMU_ID_MASK(0x2, 0xF)>,
			<13 TLB_CFG(BL1, PREFETCH_NONE) DIR_WRITE SYSMMU_ID_MASK(0x3, 0xF)>,
			<14 TLB_CFG(BL1, PREFETCH_NONE) DIR_READ SYSMMU_ID_MASK(0x4, 0xF)>,
			<9 TLB_CFG(BL1, PREFETCH_PREDICTION) DIR_WRITE SYSMMU_ID_MASK(0x5, 0x1F)>,
			<10 TLB_CFG(BL1, PREFETCH_PREDICTION) DIR_WRITE SYSMMU_ID_MASK(0xD, 0x1F)>,
			<4 TLB_CFG(BL2, PREFETCH_NONE) DIR_READ SYSMMU_ID_MASK(0x5, 0x1F)>,
			<11 TLB_CFG(BL1, PREFETCH_PREDICTION) DIR_READ SYSMMU_ID_MASK(0xD, 0x1F)>,
			<12 TLB_CFG(BL1, PREFETCH_PREDICTION) DIR_WRITE SYSMMU_ID_MASK(0x15, 0x1F)>;
		port-name = "GDC_V10.0 (M0), GDC_V10.0 (M...";
		power-domains = <&pd_lme>;
	};

	sysmmu_d_m2m: sysmmu@0x18A00000 {
		compatible = "samsung,sysmmu-v8";
		reg = <0 0x18A00000 0x9000>;
		interrupts = <0 INTREQ__M2M__SYSMMU_D_M2M_PM_S1_NS IRQ_TYPE_LEVEL_HIGH>,
				<0 INTREQ__M2M__SYSMMU_D_M2M_PM_S1_S IRQ_TYPE_LEVEL_HIGH>;
		sysmmu,secure-irq;
		sysmmu,secure_base = <0x18A10000>;
		qos = <15>;
		#iommu-cells = <0>;
		sysmmu,default_tlb = <TLB_CFG(BL32, PREFETCH_PREDICTION)>;
		sysmmu,tlb_property =
			<10 TLB_CFG(BL1, PREFETCH_NONE) DIR_READ SYSMMU_ID_MASK(0xA, 0x3F)>,
			<11 TLB_CFG(BL1, PREFETCH_PREDICTION) DIR_WRITE SYSMMU_ID_MASK(0x22, 0x3F)>,
			<12 TLB_CFG(BL1, PREFETCH_PREDICTION) DIR_WRITE SYSMMU_ID_MASK(0x32, 0x3F)>,
			<16 TLB_CFG(BL1, PREFETCH_NONE) DIR_WRITE SYSMMU_ID_MASK(0xA, 0x3F)>,
			<1 TLB_CFG(BL8, PREFETCH_NONE) DIR_RW SYSMMU_ID_MASK(0x0, 0x7)>,
			<2 TLB_CFG(BL8, PREFETCH_NONE) DIR_RW SYSMMU_ID_MASK(0x1, 0x7)>,
			<3 TLB_CFG(BL8, PREFETCH_NONE) DIR_RW SYSMMU_ID_MASK(0x3, 0x7)>,
			<7 TLB_CFG(BL8, PREFETCH_PREDICTION) DIR_READ SYSMMU_ID_MASK(0x4, 0x3F)>,
			<4 TLB_CFG(BL4, PREFETCH_PREDICTION) DIR_READ SYSMMU_ID_MASK(0xC, 0x3F)>,
			<8 TLB_CFG(BL8, PREFETCH_PREDICTION) DIR_READ SYSMMU_ID_MASK(0x14, 0x3F)>,
			<5 TLB_CFG(BL4, PREFETCH_PREDICTION) DIR_READ SYSMMU_ID_MASK(0x1C, 0x3F)>,
			<9 TLB_CFG(BL8, PREFETCH_PREDICTION) DIR_READ SYSMMU_ID_MASK(0x24, 0x3F)>,
			<13 TLB_CFG(BL1, PREFETCH_PREDICTION) DIR_READ SYSMMU_ID_MASK(0x2C, 0x3F)>,
			<6 TLB_CFG(BL4, PREFETCH_PREDICTION) DIR_WRITE SYSMMU_ID_MASK(0x4, 0x1F)>,
			<17 TLB_CFG(BL2, PREFETCH_PREDICTION) DIR_WRITE SYSMMU_ID_MASK(0xC, 0x1F)>,
			<14 TLB_CFG(BL1, PREFETCH_PREDICTION) DIR_WRITE SYSMMU_ID_MASK(0x14, 0x1F)>,
			<15 TLB_CFG(BL1, PREFETCH_PREDICTION) DIR_WRITE SYSMMU_ID_MASK(0x1C, 0x1F)>;
		port-name = "M2M, JPEG0, JPEG1, JSQZ, FRC...";
		power-domains = <&pd_m2m>;
	};

	sysmmu_d0_mcsc: sysmmu@0x15C70000 {
		compatible = "samsung,sysmmu-v8";
		reg = <0 0x15C70000 0x9000>;
		interrupts = <0 INTREQ__SYSMMU_D0_MCSC_S1_NS IRQ_TYPE_LEVEL_HIGH>,
				<0 INTREQ__SYSMMU_D0_MCSC_S1_S IRQ_TYPE_LEVEL_HIGH>;
		sysmmu,secure-irq;
		sysmmu,secure_base = <0x15C80000>;
		qos = <15>;
		#iommu-cells = <0>;
		sysmmu,default_tlb = <TLB_CFG(BL32, PREFETCH_PREDICTION)>;
		sysmmu,tlb_property =
			<1 TLB_CFG(BL1, PREFETCH_PREDICTION) DIR_READ SYSMMU_ID_MASK(0x2, 0x2)>;
		port-name = "MCFPV10.1 (M0)";
		power-domains = <&pd_mcsc>;
	};

	sysmmu_d1_mcsc: sysmmu@0x15CA0000 {
		compatible = "samsung,sysmmu-v8";
		reg = <0 0x15CA0000 0x9000>;
		interrupts = <0 INTREQ__SYSMMU_D1_MCSC_S1_NS IRQ_TYPE_LEVEL_HIGH>,
				<0 INTREQ__SYSMMU_D1_MCSC_S1_S IRQ_TYPE_LEVEL_HIGH>;
		sysmmu,secure-irq;
		sysmmu,secure_base = <0x15CB0000>;
		qos = <15>;
		#iommu-cells = <0>;
		sysmmu,default_tlb = <TLB_CFG(BL32, PREFETCH_PREDICTION)>;
		sysmmu,tlb_property =
			<1 TLB_CFG(BL1, PREFETCH_PREDICTION) DIR_READ SYSMMU_ID_MASK(0x4, 0x1F)>,
			<10 TLB_CFG(BL1, PREFETCH_NONE) DIR_READ SYSMMU_ID_MASK(0x1, 0x1F)>,
			<2 TLB_CFG(BL1, PREFETCH_PREDICTION) DIR_WRITE SYSMMU_ID_MASK(0x1, 0x1F)>,
			<3 TLB_CFG(BL1, PREFETCH_PREDICTION) DIR_WRITE SYSMMU_ID_MASK(0x5, 0x1F)>,
			<4 TLB_CFG(BL1, PREFETCH_PREDICTION) DIR_WRITE SYSMMU_ID_MASK(0x9, 0x1F)>,
			<5 TLB_CFG(BL1, PREFETCH_PREDICTION) DIR_WRITE SYSMMU_ID_MASK(0xD, 0x1F)>,
			<6 TLB_CFG(BL1, PREFETCH_PREDICTION) DIR_WRITE SYSMMU_ID_MASK(0x11, 0x1F)>,
			<7 TLB_CFG(BL1, PREFETCH_PREDICTION) DIR_WRITE SYSMMU_ID_MASK(0x2, 0x1F)>,
			<8 TLB_CFG(BL1, PREFETCH_PREDICTION) DIR_WRITE SYSMMU_ID_MASK(0xA, 0x1F)>,
			<9 TLB_CFG(BL1, PREFETCH_PREDICTION) DIR_WRITE SYSMMU_ID_MASK(0x12, 0x1F)>;
		port-name = "MCFPV10.1 (M2), MCSCV10.1 (M...";
		power-domains = <&pd_mcsc>;
	};

	sysmmu_d2_mcsc: sysmmu@0x15CD0000 {
		compatible = "samsung,sysmmu-v8";
		reg = <0 0x15CD0000 0x9000>;
		interrupts = <0 INTREQ__SYSMMU_D2_MCSC_S1_NS IRQ_TYPE_LEVEL_HIGH>,
				<0 INTREQ__SYSMMU_D2_MCSC_S1_S IRQ_TYPE_LEVEL_HIGH>;
		sysmmu,secure-irq;
		sysmmu,secure_base = <0x15CE0000>;
		qos = <15>;
		#iommu-cells = <0>;
		sysmmu,default_tlb = <TLB_CFG(BL32, PREFETCH_PREDICTION)>;
		sysmmu,tlb_property =
			<1 TLB_CFG(BL1, PREFETCH_PREDICTION) DIR_READ SYSMMU_ID_MASK(0x4, 0x1F)>,
			<2 TLB_CFG(BL1, PREFETCH_PREDICTION) DIR_WRITE SYSMMU_ID_MASK(0x1, 0x1F)>,
			<3 TLB_CFG(BL1, PREFETCH_PREDICTION) DIR_WRITE SYSMMU_ID_MASK(0x9, 0x1F)>,
			<4 TLB_CFG(BL1, PREFETCH_PREDICTION) DIR_WRITE SYSMMU_ID_MASK(0x11, 0x1F)>,
			<5 TLB_CFG(BL1, PREFETCH_PREDICTION) DIR_WRITE SYSMMU_ID_MASK(0x2, 0x1F)>,
			<6 TLB_CFG(BL1, PREFETCH_PREDICTION) DIR_WRITE SYSMMU_ID_MASK(0xA, 0x1F)>,
			<7 TLB_CFG(BL1, PREFETCH_PREDICTION) DIR_WRITE SYSMMU_ID_MASK(0x12, 0x1F)>;
		port-name = "MCFPV10.1 (M3), MCSCV10.1 (M...";
		power-domains = <&pd_mcsc>;
	};

	sysmmu_d3_mcsc: sysmmu@0x15D00000 {
		compatible = "samsung,sysmmu-v8";
		reg = <0 0x15D00000 0x9000>;
		interrupts = <0 INTREQ__SYSMMU_D3_MCSC_S1_NS IRQ_TYPE_LEVEL_HIGH>,
				<0 INTREQ__SYSMMU_D3_MCSC_S1_S IRQ_TYPE_LEVEL_HIGH>;
		sysmmu,secure-irq;
		sysmmu,secure_base = <0x15D10000>;
		qos = <15>;
		#iommu-cells = <0>;
		sysmmu,default_tlb = <TLB_CFG(BL16, PREFETCH_PREDICTION)>;
		sysmmu,tlb_property =
			<1 TLB_CFG(BL1, PREFETCH_PREDICTION) DIR_READ SYSMMU_ID_MASK(0x1, 0x7)>,
			<4 TLB_CFG(BL1, PREFETCH_NONE) DIR_READ SYSMMU_ID_MASK(0x2, 0x7)>,
			<5 TLB_CFG(BL1, PREFETCH_PREDICTION) DIR_WRITE SYSMMU_ID_MASK(0x0, 0x7)>,
			<2 TLB_CFG(BL1, PREFETCH_PREDICTION) DIR_WRITE SYSMMU_ID_MASK(0x1, 0x7)>,
			<3 TLB_CFG(BL1, PREFETCH_PREDICTION) DIR_WRITE SYSMMU_ID_MASK(0x5, 0x7)>;
		port-name = "MCFPV10.1 (M4), MCFPV10.1 (M...";
		power-domains = <&pd_mcsc>;
	};

	sysmmu_d4_mcsc: sysmmu@0x15D30000 {
		compatible = "samsung,sysmmu-v8";
		reg = <0 0x15D30000 0x9000>;
		interrupts = <0 INTREQ__SYSMMU_D4_MCSC_S1_NS IRQ_TYPE_LEVEL_HIGH>,
				<0 INTREQ__SYSMMU_D4_MCSC_S1_S IRQ_TYPE_LEVEL_HIGH>;
		sysmmu,secure-irq;
		sysmmu,secure_base = <0x15D40000>;
		qos = <15>;
		#iommu-cells = <0>;
		sysmmu,default_tlb = <TLB_CFG(BL1, PREFETCH_PREDICTION)>;
		sysmmu,tlb_property =
			<1 TLB_CFG(BL1, PREFETCH_PREDICTION) DIR_READ SYSMMU_ID_MASK(0x1, 0x3F)>,
			<2 TLB_CFG(BL1, PREFETCH_PREDICTION) DIR_READ SYSMMU_ID_MASK(0x2, 0x3F)>,
			<3 TLB_CFG(BL1, PREFETCH_PREDICTION) DIR_READ SYSMMU_ID_MASK(0x3, 0x3F)>,
			<4 TLB_CFG(BL1, PREFETCH_PREDICTION) DIR_READ SYSMMU_ID_MASK(0x4, 0x3F)>,
			<5 TLB_CFG(BL1, PREFETCH_PREDICTION) DIR_WRITE SYSMMU_ID_MASK(0x0, 0x3F)>,
			<6 TLB_CFG(BL1, PREFETCH_PREDICTION) DIR_WRITE SYSMMU_ID_MASK(0x8, 0x3F)>,
			<7 TLB_CFG(BL1, PREFETCH_PREDICTION) DIR_READ SYSMMU_ID_MASK(0x5, 0x3F)>,
			<8 TLB_CFG(BL1, PREFETCH_PREDICTION) DIR_READ SYSMMU_ID_MASK(0xD, 0x3F)>,
			<9 TLB_CFG(BL1, PREFETCH_PREDICTION) DIR_WRITE SYSMMU_ID_MASK(0x5, 0x3F)>,
			<10 TLB_CFG(BL1, PREFETCH_PREDICTION) DIR_WRITE SYSMMU_ID_MASK(0xD, 0x3F)>,
			<11 TLB_CFG(BL1, PREFETCH_PREDICTION) DIR_WRITE SYSMMU_ID_MASK(0x15, 0x3F)>,
			<12 TLB_CFG(BL1, PREFETCH_PREDICTION) DIR_WRITE SYSMMU_ID_MASK(0x1D, 0x3F)>,
			<13 TLB_CFG(BL1, PREFETCH_PREDICTION) DIR_WRITE SYSMMU_ID_MASK(0x25, 0x3F)>,
			<14 TLB_CFG(BL1, PREFETCH_NONE) DIR_WRITE SYSMMU_ID_MASK(0x6, 0xF)>,
			<15 TLB_CFG(BL1, PREFETCH_NONE) DIR_WRITE SYSMMU_ID_MASK(0x7, 0xF)>;
		port-name = "MCFPV10.1 (M6), MCFPV10.1 (M...";
		power-domains = <&pd_mcsc>;
	};

	sysmmu_d0_mfc0: sysmmu@0x18670000 {
		compatible = "samsung,sysmmu-v8";
		reg = <0 0x18670000 0x9000>;
		interrupts = <0 INTREQ__SYSMMU_MFC0D0_interrupt_s1_ns IRQ_TYPE_LEVEL_HIGH>,
				<0 INTREQ__SYSMMU_MFC0D0_interrupt_s1_s IRQ_TYPE_LEVEL_HIGH>;
		sysmmu,async-fault;
		sysmmu,secure-irq;
		sysmmu,secure_base = <0x18680000>;
		qos = <15>;
		#iommu-cells = <0>;
		sysmmu,default_tlb = <TLB_CFG(BL4, PREFETCH_NONE)>;
		port-name = "FIMV_MFCM_V16.0 (M0)";
		power-domains = <&pd_mfc0>;
	};

	sysmmu_d1_mfc0: sysmmu@0x186A0000 {
		compatible = "samsung,sysmmu-v8";
		reg = <0 0x186A0000 0xA000>;
		interrupts = <0 INTREQ__SYSMMU_MFC0D1_interrupt_s1_ns IRQ_TYPE_LEVEL_HIGH>,
				<0 INTREQ__SYSMMU_MFC0D1_interrupt_s1_s IRQ_TYPE_LEVEL_HIGH>;
		sysmmu,async-fault;
		sysmmu,secure-irq;
		sysmmu,secure_base = <0x186B0000>;
		qos = <15>;
		vmid_mask = <0x3>;
		#iommu-cells = <0>;
		sysmmu,default_tlb = <TLB_CFG(BL4, PREFETCH_PREDICTION)>;
		sysmmu,tlb_property =
			<2 TLB_CFG(BL1, PREFETCH_NONE) DIR_WRITE SYSMMU_ID_MASK(0x1, 0x3)>,
			<1 TLB_CFG(BL1, PREFETCH_NONE) DIR_RW SYSMMU_ID_MASK(0x2, 0x3)>;
		port-name = "FIMV_MFCM_V16.0 (M1), FIMV_M...";
		power-domains = <&pd_mfc0>;
	};

	sysmmu_d0_mfc1: sysmmu@0x18870000 {
		compatible = "samsung,sysmmu-v8";
		reg = <0 0x18870000 0x9000>;
		interrupts = <0 INTREQ__SYSMMU_MFC1D0_interrupt_s1_ns IRQ_TYPE_LEVEL_HIGH>,
				<0 INTREQ__SYSMMU_MFC1D0_interrupt_s1_s IRQ_TYPE_LEVEL_HIGH>;
		sysmmu,async-fault;
		sysmmu,secure-irq;
		sysmmu,secure_base = <0x18880000>;
		qos = <15>;
		#iommu-cells = <0>;
		sysmmu,default_tlb = <TLB_CFG(BL4, PREFETCH_NONE)>;
		port-name = "FIMV_MFCS_V16.0 (M0)";
		power-domains = <&pd_mfc1>;
	};

	sysmmu_d1_mfc1: sysmmu@0x188A0000 {
		compatible = "samsung,sysmmu-v8";
		reg = <0 0x188A0000 0x9000>;
		interrupts = <0 INTREQ__SYSMMU_MFC1D1_interrupt_s1_ns IRQ_TYPE_LEVEL_HIGH>,
				<0 INTREQ__SYSMMU_MFC1D1_interrupt_s1_s IRQ_TYPE_LEVEL_HIGH>;
		sysmmu,async-fault;
		sysmmu,secure-irq;
		sysmmu,secure_base = <0x188B0000>;
		qos = <15>;
		#iommu-cells = <0>;
		sysmmu,default_tlb = <TLB_CFG(BL4, PREFETCH_PREDICTION)>;
		port-name = "FIMV_MFCS_V16.0 (M1)";
		power-domains = <&pd_mfc1>;
	};

	sysmmu_d0_yuvp: sysmmu@0x18070000 {
		compatible = "samsung,sysmmu-v8";
		reg = <0 0x18070000 0x9000>;
		interrupts = <0 INTREQ__SYSMMU_D0_YUVP_S1_NS IRQ_TYPE_LEVEL_HIGH>,
				<0 INTREQ__SYSMMU_D0_YUVP_S1_S IRQ_TYPE_LEVEL_HIGH>;
		sysmmu,secure-irq;
		sysmmu,secure_base = <0x18080000>;
		qos = <15>;
		#iommu-cells = <0>;
		sysmmu,default_tlb = <TLB_CFG(BL1, PREFETCH_PREDICTION)>;
		sysmmu,tlb_property =
			<1 TLB_CFG(BL1, PREFETCH_PREDICTION) DIR_WRITE SYSMMU_ID_MASK(0x1, 0x3)>,
			<6 TLB_CFG(BL1, PREFETCH_NONE) DIR_READ SYSMMU_ID_MASK(0x0, 0x3)>,
			<4 TLB_CFG(BL1, PREFETCH_NONE) DIR_WRITE SYSMMU_ID_MASK(0x0, 0x3)>,
			<2 TLB_CFG(BL1, PREFETCH_PREDICTION) DIR_READ SYSMMU_ID_MASK(0x2, 0x3)>,
			<3 TLB_CFG(BL1, PREFETCH_PREDICTION) DIR_WRITE SYSMMU_ID_MASK(0x2, 0x3)>,
			<5 TLB_CFG(BL1, PREFETCH_NONE) DIR_WRITE SYSMMU_ID_MASK(0x3, 0x3)>;
		port-name = "YUVP_M1_Y_Y, YUVP_M0_CL_VOTF...";
		power-domains = <&pd_yuvp>;
	};

	sysmmu_d1_yuvp: sysmmu@0x180A0000 {
		compatible = "samsung,sysmmu-v8";
		reg = <0 0x180A0000 0x9000>;
		interrupts = <0 INTREQ__SYSMMU_D1_YUVP_S1_NS IRQ_TYPE_LEVEL_HIGH>,
				<0 INTREQ__SYSMMU_D1_YUVP_S1_S IRQ_TYPE_LEVEL_HIGH>;
		sysmmu,secure-irq;
		sysmmu,secure_base = <0x180B0000>;
		qos = <15>;
		#iommu-cells = <0>;
		sysmmu,default_tlb = <TLB_CFG(BL1, PREFETCH_PREDICTION)>;
		sysmmu,tlb_property =
			<1 TLB_CFG(BL1, PREFETCH_PREDICTION) DIR_READ SYSMMU_ID_MASK(0x1, 0x3)>,
			<2 TLB_CFG(BL1, PREFETCH_PREDICTION) DIR_READ SYSMMU_ID_MASK(0x2, 0x3)>,
			<3 TLB_CFG(BL1, PREFETCH_NONE) DIR_READ SYSMMU_ID_MASK(0x3, 0x3)>;
		port-name = "YUVP_M3_SEG_x, YUVP_M4_DRC0_...";
		power-domains = <&pd_yuvp>;
	};
};
